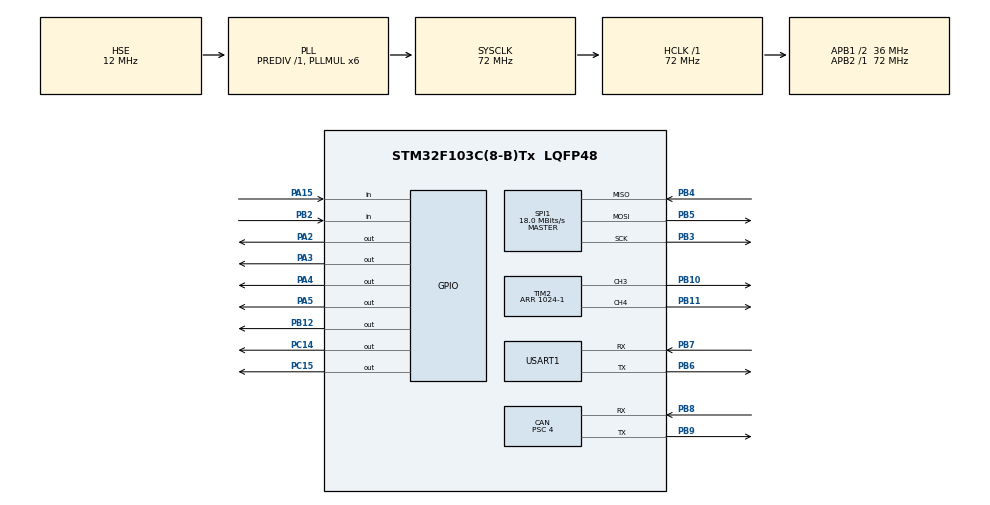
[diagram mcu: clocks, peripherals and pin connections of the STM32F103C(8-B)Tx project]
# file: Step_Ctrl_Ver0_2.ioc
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CAN.BS1=CAN_BS1_9TQ
CAN.BS2=CAN_BS2_8TQ
CAN.CalculateBaudRate=500000
CAN.CalculateTimeBit=2000
CAN.CalculateTimeQuantum=111.11111111111111
CAN.Prescaler=4
Mcu.Family=STM32F1
Mcu.Name=STM32F103C(8-B)Tx
Mcu.Package=LQFP48
NVIC.PriorityGroup=NVIC_PRIORITYGROUP_4
NVIC.TIM3_IRQn=true\:0\:0\:false\:false\:true\:true\:true\:true
NVIC.USB_LP_CAN1_RX0_IRQn=true\:1\:0\:true\:false\:true\:true\:true\:true
PA13.Mode=Serial_Wire
PA13.Signal=SYS_JTMS-SWDIO
PA14.Mode=Serial_Wire
PA14.Signal=SYS_JTCK-SWCLK
PA15.GPIO_PuPd=GPIO_PULLUP
PA15.Signal=GPIO_Input
PA2.GPIO_Speed=GPIO_SPEED_FREQ_HIGH
PA2.Signal=GPIO_Output
PA3.GPIO_Speed=GPIO_SPEED_FREQ_HIGH
PA3.Signal=GPIO_Output
PA4.GPIO_Speed=GPIO_SPEED_FREQ_HIGH
PA4.Signal=GPIO_Output
PA5.GPIO_Speed=GPIO_SPEED_FREQ_HIGH
PA5.Signal=GPIO_Output
PB10.Signal=S_TIM2_CH3
PB11.Signal=S_TIM2_CH4
PB12.GPIO_Speed=GPIO_SPEED_FREQ_HIGH
PB12.PinState=GPIO_PIN_SET
PB12.Signal=GPIO_Output
PB2.GPIO_PuPd=GPIO_PULLUP
PB2.Signal=GPIO_Input
PB3.Mode=Full_Duplex_Master
PB3.Signal=SPI1_SCK
PB4.Mode=Full_Duplex_Master
PB4.Signal=SPI1_MISO
PB5.Mode=Full_Duplex_Master
PB5.Signal=SPI1_MOSI
PB6.Mode=Asynchronous
PB6.Signal=USART1_TX
PB7.Mode=Asynchronous
PB7.Signal=USART1_RX
PB8.Mode=CAN_Activate
PB8.Signal=CAN_RX
PB9.Mode=CAN_Activate
PB9.Signal=CAN_TX
PC14-OSC32_IN.PinState=GPIO_PIN_SET
PC14-OSC32_IN.Signal=GPIO_Output
PC15-OSC32_OUT.PinState=GPIO_PIN_SET
PC15-OSC32_OUT.Signal=GPIO_Output
PD0-OSC_IN.Mode=HSE-External-Oscillator
PD0-OSC_IN.Signal=RCC_OSC_IN
PD1-OSC_OUT.Mode=HSE-External-Oscillator
PD1-OSC_OUT.Signal=RCC_OSC_OUT
ProjectManager.HeapSize=0x200
ProjectManager.StackSize=0x400
ProjectManager.TargetToolchain=MDK-ARM V5.32
RCC.AHBFreq_Value=72000000
RCC.APB1CLKDivider=RCC_HCLK_DIV2
RCC.APB1Freq_Value=36000000
RCC.APB1TimFreq_Value=72000000
RCC.APB2Freq_Value=72000000
RCC.APB2TimFreq_Value=72000000
RCC.HCLKFreq_Value=72000000
RCC.HSE_VALUE=12000000
RCC.PLLMUL=RCC_PLL_MUL6
RCC.PLLSourceVirtual=RCC_PLLSOURCE_HSE
RCC.SYSCLKFreq_VALUE=72000000
RCC.SYSCLKSource=RCC_SYSCLKSOURCE_PLLCLK
RCC.USBFreq_Value=72000000
SH.S_TIM2_CH3.0=TIM2_CH3,PWM Generation3 CH3
SH.S_TIM2_CH4.0=TIM2_CH4,PWM Generation4 CH4
SPI1.BaudRatePrescaler=SPI_BAUDRATEPRESCALER_4
SPI1.CLKPhase=SPI_PHASE_2EDGE
SPI1.CLKPolarity=SPI_POLARITY_HIGH
SPI1.CalculateBaudRate=18.0 MBits/s
SPI1.DataSize=SPI_DATASIZE_16BIT
SPI1.Direction=SPI_DIRECTION_2LINES
SPI1.Mode=SPI_MODE_MASTER
SPI1.VirtualType=VM_MASTER
TIM2.AutoReloadPreload=TIM_AUTORELOAD_PRELOAD_ENABLE
TIM2.Channel-PWM\ Generation3\ CH3=TIM_CHANNEL_3
TIM2.Channel-PWM\ Generation4\ CH4=TIM_CHANNEL_4
TIM2.Period=1024-1
TIM3.Period=3600-1
TIM3.Prescaler=0
USART1.VirtualMode=VM_ASYNC
VP_TIM3_VS_ClockSourceINT.Mode=Internal
board=custom

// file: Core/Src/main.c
/* USER CODE BEGIN Header */
/**
  ******************************************************************************
  * @file           : main.c
  * @brief          : Main program body
  ******************************************************************************
  * @attention
  *
  * Copyright (c) 2023 STMicroelectronics.
  * All rights reserved.
  *
  * This software is licensed under terms that can be found in the LICENSE file
  * in the root directory of this software component.
  * If no LICENSE file comes with this software, it is provided AS-IS.
  *
  ******************************************************************************
  */
/* USER CODE END Header */
#include "main.h"
#include "can.h"
#include "spi.h"
#include "tim.h"
#include "usart.h"
#include "gpio.h"

/* USER CODE BEGIN Includes */
#include "Del_Hal.h"
/* USER CODE END Includes */

void SystemClock_Config(void);

int main(void)
{

  /* MCU Configuration--------------------------------------------------------*/

  /* Reset of all peripherals, Initializes the Flash interface and the Systick. */
  HAL_Init();

  /* Configure the system clock */
  SystemClock_Config();

  /* Initialize all configured peripherals */
  MX_GPIO_Init();
  MX_USART1_UART_Init();
  MX_SPI1_Init();
  MX_TIM2_Init();
  MX_TIM3_Init();
  MX_CAN_Init();

  /* Infinite loop */
  /* USER CODE BEGIN WHILE */
	Del_Init();
  while (1)
  {
		Del_Update();
    /* USER CODE END WHILE */

  }
}

void SystemClock_Config(void)
{
  RCC_OscInitTypeDef RCC_OscInitStruct = {0};
  RCC_ClkInitTypeDef RCC_ClkInitStruct = {0};

  /** Initializes the RCC Oscillators according to the specified parameters
  * in the RCC_OscInitTypeDef structure.
  */
  RCC_OscInitStruct.OscillatorType = RCC_OSCILLATORTYPE_HSE;
  RCC_OscInitStruct.HSEState = RCC_HSE_ON;
  RCC_OscInitStruct.HSEPredivValue = RCC_HSE_PREDIV_DIV1;
  RCC_OscInitStruct.HSIState = RCC_HSI_ON;
  RCC_OscInitStruct.PLL.PLLState = RCC_PLL_ON;
  RCC_OscInitStruct.PLL.PLLSource = RCC_PLLSOURCE_HSE;
  RCC_OscInitStruct.PLL.PLLMUL = RCC_PLL_MUL6;
  if (HAL_RCC_OscConfig(&RCC_OscInitStruct) != HAL_OK)
  {
    Error_Handler();
  }

  /** Initializes the CPU, AHB and APB buses clocks
  */
  RCC_ClkInitStruct.ClockType = RCC_CLOCKTYPE_HCLK|RCC_CLOCKTYPE_SYSCLK
                              |RCC_CLOCKTYPE_PCLK1|RCC_CLOCKTYPE_PCLK2;
  RCC_ClkInitStruct.SYSCLKSource = RCC_SYSCLKSOURCE_PLLCLK;
  RCC_ClkInitStruct.AHBCLKDivider = RCC_SYSCLK_DIV1;
  RCC_ClkInitStruct.APB1CLKDivider = RCC_HCLK_DIV2;
  RCC_ClkInitStruct.APB2CLKDivider = RCC_HCLK_DIV1;

  if (HAL_RCC_ClockConfig(&RCC_ClkInitStruct, FLASH_LATENCY_2) != HAL_OK)
  {
    Error_Handler();
  }
}

void Error_Handler(void)
{
  __disable_irq();
  while (1)
  {
  }
}
